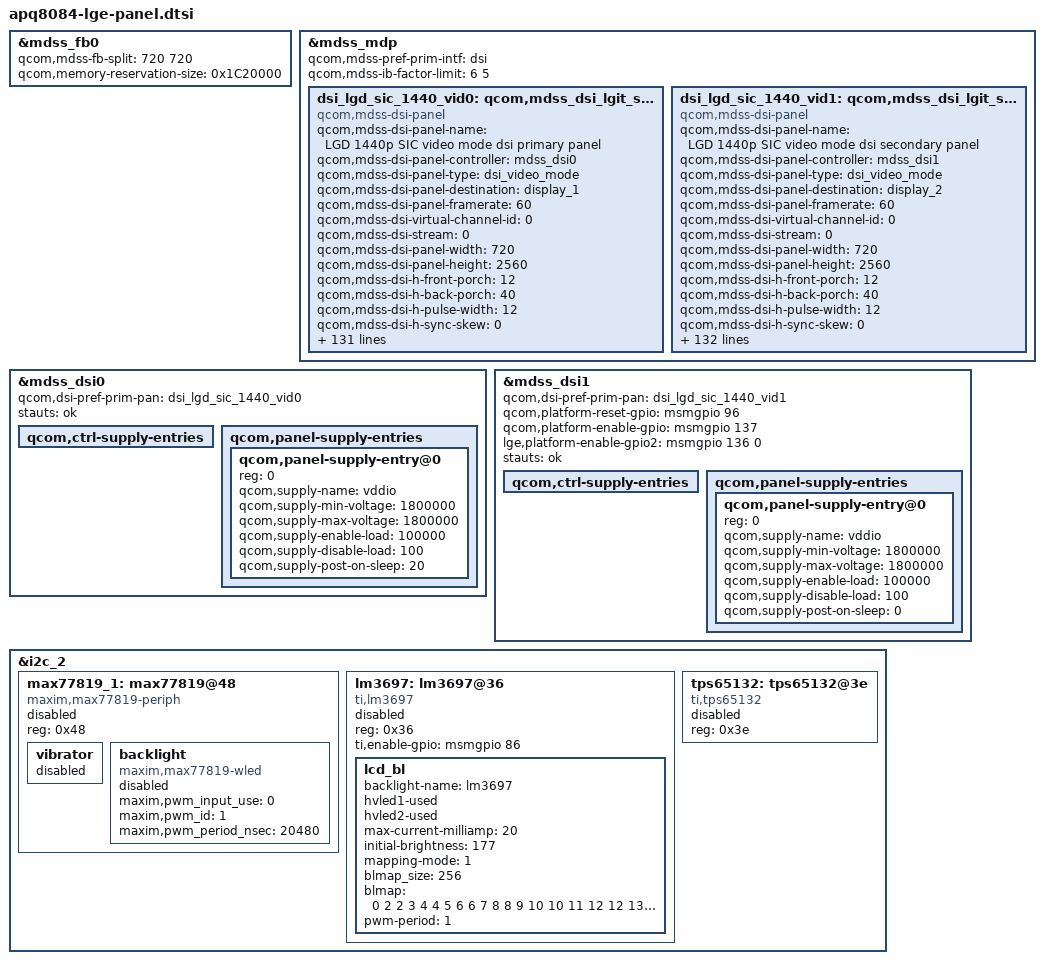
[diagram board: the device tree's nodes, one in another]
/* Copyright (c) 2012, Code Aurora Forum. All rights reserved.
 *
 * This program is free software; you can redistribute it and/or modify
 * it under the terms of the GNU General Public License version 2 and
 * only version 2 as published by the Free Software Foundation.
 *
 * This program is distributed in the hope that it will be useful,
 * but WITHOUT ANY WARRANTY; without even the implied warranty of
 * MERCHANTABILITY or FITNESS FOR A PARTICULAR PURPOSE.  See the
 * GNU General Public License for more details.
 */
&mdss_fb0 {
	/delete-property/ qcom,mdss-fb-splash-logo-enabled;
	qcom,mdss-fb-split = <720 720>;
	qcom,memory-reservation-size = <0x1C20000>;
};

&mdss_mdp {

	/delete-property/ qcom,mdss-ad-off;
    /delete-property/ qcom,mdss-has-source-split;
	qcom,mdss-pref-prim-intf = "dsi";
	qcom,mdss-ib-factor-limit = <6 5>;	/*  vt tuning times  */

	dsi_lgd_sic_1440_vid0: qcom,mdss_dsi_lgit_sic_mipi0_video {
		compatible = "qcom,mdss-dsi-panel";
		qcom,mdss-dsi-panel-name = "LGD 1440p SIC video mode dsi primary panel";
		qcom,mdss-dsi-panel-controller = <&mdss_dsi0>;
		qcom,mdss-dsi-panel-type = "dsi_video_mode";
		qcom,mdss-dsi-panel-destination = "display_1";
		qcom,mdss-dsi-panel-framerate = <60>;
		qcom,mdss-dsi-virtual-channel-id = <0>;
		qcom,mdss-dsi-stream = <0>;
		qcom,mdss-dsi-panel-width = <720>;
		qcom,mdss-dsi-panel-height = <2560>;
		qcom,mdss-dsi-h-front-porch = <12>;
		qcom,mdss-dsi-h-back-porch = <40>;
		qcom,mdss-dsi-h-pulse-width = <12>;
		qcom,mdss-dsi-h-sync-skew = <0>;
		qcom,mdss-dsi-v-back-porch = <5>;
		qcom,mdss-dsi-v-front-porch = <5>;
		qcom,mdss-dsi-v-pulse-width = <1>;
		qcom,mdss-dsi-h-left-border = <0>;
		qcom,mdss-dsi-h-right-border = <0>;
		qcom,mdss-dsi-v-top-border = <0>;
		qcom,mdss-dsi-v-bottom-border = <0>;
		qcom,mdss-dsi-bpp = <24>;
		qcom,mdss-dsi-color-order = "rgb_swap_rgb";
		qcom,mdss-dsi-underflow-color = <0x71>;
		qcom,mdss-dsi-border-color = <0>;
		qcom,mdss-dsi-on-command = [
			// SW reset
			05 01 00 00 05 00 01 01
			// Manufacturer Command Protection
			15 01 00 00 00 00 02 B0 AC
			// MIPI DSI Configuration
			39 01 00 00 00 00 06 B1 47 F0 80 00 00
			// MIPI DSI BIAS
			39 01 00 00 00 00 04 B2 77 28 27
			// Display Control. B3 ~ B5 : Control1 ~ Control3
			39 01 00 00 00 00 07 B3 0F 12 22 20 00 A0
			39 01 00 00 00 00 08 B4 13 10 10 0A 0A 0A 0A
			39 01 00 00 00 00 0A B5 30 26 1A 1A 10 10 40 10 05
			// Panel Setting
			39 01 00 00 00 00 04 B7 62 01 3F
			39 01 00 00 00 00 07 B8 00 00 00 47 7F 80
			39 01 00 00 00 00 03 C0 03 00
			39 01 00 00 00 00 06 C1 22 80 F0 01 CF
			// Power Control. C2 ~ C5 : Control2 ~ Control5
			15 01 00 00 00 00 02 C2 22
			39 01 00 00 00 00 07 C3 06 88 0C 00 1B 1B
			39 01 00 00 00 00 04 C4 47 0C 0C
			39 01 00 00 00 00 07 C5 41 81 05 05 59 02
			// Video Sync Output Control
			39 01 00 00 00 00 03 CA 20 B9
			// Abrupt Power Detect Configuration
			39 01 00 00 00 00 02 C9 3F
			// Gamma. P : Posi., N : Nega., R : Red, G : Green, B : Blue
			// D0 : PR, D1 : NR, D2 : PG, D3 : NG, D4 : PB, D5 : NB
			39 01 00 00 00 00 0C D0 03 30 35 55 22 34 0F 06 51 33 02
			39 01 00 00 00 00 0C D1 03 30 35 55 22 34 0F 06 51 33 02
			39 01 00 00 00 00 0C D2 03 30 35 55 22 34 0F 06 51 33 02
			39 01 00 00 00 00 0C D3 03 30 35 55 22 34 0F 06 51 33 02
			39 01 00 00 00 00 0C D4 03 30 35 55 22 34 0F 06 51 33 02
			39 01 00 00 00 00 0C D5 03 30 35 55 22 34 0F 06 51 33 02
			// Test 2
			39 01 00 00 00 00 05 E9 00 00 00 00
			// Pamper Control
			39 01 00 00 00 00 03 B6 00 00
			15 01 00 00 00 00 02 51 FF
			15 01 00 00 00 00 02 5E 00
			15 01 00 00 00 00 02 53 2C
			// 12.5%, 20kHz
			39 01 00 00 00 00 07 B8 11 11 11 38 00 00
			15 01 00 00 00 00 02 55 81
			15 01 00 00 00 00 02 F0 33
			// Contrast
			39 01 00 00 00 00 05 F1 00 00 02 02
			// Sharpness
			39 01 00 00 00 00 04 F2 01 00 40
			// Color enhancement
			39 01 00 00 00 00 06 F3 00 00 00 00 00
			// Selective Color. F4 ~ F7 : Color0 ~ Color4
			39 01 00 00 00 00 02 F4 05
			39 01 00 00 00 00 04 F5 02 00 83
			39 01 00 00 00 00 04 F6 00 00 00
			39 01 00 00 00 00 04 F7 00 00 00
			// Digital Gamma. RGB
			39 01 00 00 00 00 11 F8 40 40 40 40 40 40 40 40 00 00 00 00 00 00 00 00
			39 01 00 00 00 00 11 F9 40 40 40 40 40 40 40 40 00 00 00 00 00 00 00 00
			39 01 00 00 00 00 11 FA 40 40 40 40 40 40 40 40 00 00 00 00 00 00 00 00
			// sleep out delay 5ms
			05 01 00 00 05 00 01 11
			// display on delay 0ms
			05 01 00 00 00 00 01 29
			];
		qcom,mdss-dsi-off-command = [05 01 00 00 14 00 01 28
			05 01 00 00 50 00 01 10];
		qcom,mdss-dsi-on-command-state = "dsi_lp_mode";
		qcom,mdss-dsi-off-command-state = "dsi_hs_mode";
		qcom,mdss-dsi-h-sync-pulse = <0>;
		qcom,mdss-dsi-traffic-mode = "non_burst_sync_event";
		qcom,mdss-dsi-lane-map = "lane_map_0123";
		qcom,mdss-dsi-lane-hs = <1>;
		qcom,mdss-dsi-bllp-eof-power-mode;
		qcom,mdss-dsi-bllp-power-mode;
		qcom,mdss-dsi-lane-0-state;
		qcom,mdss-dsi-lane-1-state;
		qcom,mdss-dsi-lane-2-state;
		qcom,mdss-dsi-lane-3-state;
		qcom,cmd-sync-wait-broadcast;
		qcom,mdss-dsi-panel-timings = [C5 2C 1E 00 5A 5E
			22 30 25 03 04 00];
		qcom,mdss-dsi-t-clk-post = <0x03>;
		qcom,mdss-dsi-t-clk-pre = <0x25>;
		qcom,mdss-dsi-bl-min-level = <1>;
		qcom,mdss-dsi-bl-max-level = <255>;
		qcom,mdss-dsi-dma-trigger = "trigger_sw";
		qcom,mdss-dsi-mdp-trigger = "none";
		qcom,mdss-dsi-bl-pmic-control-type = "bl_others";
		qcom,mdss-dsi-reset-sequence = <1 5>;
		qcom,cont-splash-enabled;
		qcom,mdss-dsi-lp11-init;
		qcom,mdss-dsi-tx-eot-append;
		qcom,mdss-dsi-sharpening-lv0 = [ 39 01 00 00 00 00 04 F2 01 00 00 ]; 
		qcom,mdss-dsi-sharpening-lv1 = [ 39 01 00 00 00 00 04 F2 01 00 01 ]; 
		qcom,mdss-dsi-sharpening-lv2 = [ 39 01 00 00 00 00 04 F2 01 00 02 ]; 
		qcom,mdss-dsi-sharpening-lv3 = [ 39 01 00 00 00 00 04 F2 01 00 03 ]; 
		qcom,mdss-dsi-sharpening-lv4 = [ 39 01 00 00 00 00 04 F2 01 00 04 ]; 
		qcom,mdss-dsi-sharpening-lv5 = [ 39 01 00 00 00 00 04 F2 01 00 05 ]; 
		qcom,mdss-dsi-sharpening-lv6 = [ 39 01 00 00 00 00 04 F2 01 00 06 ]; 
		qcom,mdss-dsi-sharpening-lv7 = [ 39 01 00 00 00 00 04 F2 01 00 07 ]; 
		qcom,mdss-dsi-sharpening-lv8 = [ 39 01 00 00 00 00 04 F2 01 00 08 ]; 
		qcom,mdss-dsi-sharpening-lv9 = [ 39 01 00 00 00 00 04 F2 01 00 09 ]; 
		qcom,mdss-dsi-sharpening-lv10 = [ 39 01 00 00 00 00 04 F2 01 00 10 ]; 
		qcom,mdss-dsi-sharpening-lv11 = [ 39 01 00 00 00 00 04 F2 01 00 11 ]; 
		qcom,mdss-dsi-sharpening-lv12 = [ 39 01 00 00 00 00 04 F2 01 00 12 ]; 
		qcom,mdss-dsi-sharpening-lv13 = [ 39 01 00 00 00 00 04 F2 01 00 13 ]; 
		qcom,mdss-dsi-sharpening-lv14 = [ 39 01 00 00 00 00 04 F2 01 00 14 ]; 
		qcom,mdss-dsi-sharpening-lv15 = [ 39 01 00 00 00 00 04 F2 01 00 15 ]; 
		qcom,mdss-dsi-sharpening-lv16 = [ 39 01 00 00 00 00 04 F2 01 00 16 ]; 
		qcom,mdss-dsi-sharpening-lv17 = [ 39 01 00 00 00 00 04 F2 01 00 17 ]; 
		qcom,mdss-dsi-sharpening-lv18 = [ 39 01 00 00 00 00 04 F2 01 00 18 ]; 
		qcom,mdss-dsi-sharpening-lv19 = [ 39 01 00 00 00 00 04 F2 01 00 19 ]; 
		qcom,mdss-dsi-sharpening-lv20 = [ 39 01 00 00 00 00 04 F2 01 00 20 ]; 
		qcom,mdss-dsi-sharpening-lv21 = [ 39 01 00 00 00 00 04 F2 01 00 21 ]; 
		qcom,mdss-dsi-sharpening-lv22 = [ 39 01 00 00 00 00 04 F2 01 00 22 ]; 
		qcom,mdss-dsi-sharpening-lv23 = [ 39 01 00 00 00 00 04 F2 01 00 23 ]; 
		qcom,mdss-dsi-sharpening-lv24 = [ 39 01 00 00 00 00 04 F2 01 00 24 ]; 
		qcom,mdss-dsi-sharpening-lv25 = [ 39 01 00 00 00 00 04 F2 01 00 25 ]; 
		qcom,mdss-dsi-sharpening-lv26 = [ 39 01 00 00 00 00 04 F2 01 00 26 ]; 
		qcom,mdss-dsi-sharpening-lv27 = [ 39 01 00 00 00 00 04 F2 01 00 27 ]; 
		qcom,mdss-dsi-sharpening-lv28 = [ 39 01 00 00 00 00 04 F2 01 00 28 ]; 
		qcom,mdss-dsi-sharpening-lv29 = [ 39 01 00 00 00 00 04 F2 01 00 29 ]; 
		qcom,mdss-dsi-sharpening-lv30 = [ 39 01 00 00 00 00 04 F2 01 00 30 ]; 
		qcom,mdss-dsi-sharpening-lv31 = [ 39 01 00 00 00 00 04 F2 01 00 31 ]; 
		qcom,mdss-dsi-sharpening-lv32 = [ 39 01 00 00 00 00 04 F2 01 00 32 ]; 
		qcom,mdss-dsi-sharpening-lv33 = [ 39 01 00 00 00 00 04 F2 01 00 33 ]; 
		qcom,mdss-dsi-sharpening-lv34 = [ 39 01 00 00 00 00 04 F2 01 00 34 ]; 
		qcom,mdss-dsi-sharpening-lv35 = [ 39 01 00 00 00 00 04 F2 01 00 35 ]; 
		qcom,mdss-dsi-sharpening-lv36 = [ 39 01 00 00 00 00 04 F2 01 00 36 ]; 
		qcom,mdss-dsi-sharpening-lv37 = [ 39 01 00 00 00 00 04 F2 01 00 37 ]; 
		qcom,mdss-dsi-sharpening-lv38 = [ 39 01 00 00 00 00 04 F2 01 00 38 ]; 
		qcom,mdss-dsi-sharpening-lv39 = [ 39 01 00 00 00 00 04 F2 01 00 39 ]; 
		qcom,mdss-dsi-sharpening-lv40 = [ 39 01 00 00 00 00 04 F2 01 00 40 ];
 		qcom,mdss-dsi-sharpening-mode = "dsi_hs_mode";

		// ief
		qcom,panel-ief-on-cmds = [
			15 01 00 00 00 00 02 B0 AC
			15 01 00 00 00 00 02 55 81
			15 01 00 00 00 00 02 F0 7F
			39 01 00 00 00 00 05 F1 00 00 01 01
			39 01 00 00 00 00 04 F2 04 00 80
			39 01 00 00 00 00 06 F3 00 00 00 00 00
			39 01 00 00 00 00 03 F4 00 14
			39 01 00 00 00 00 04 F5 07 00 03
			39 01 00 00 00 00 04 F6 00 00 00
			39 01 00 00 00 00 04 F7 00 00 00
			39 01 00 00 00 00 11 F8 40 40 40 40 40 40 40 40 00 00 00 00 00 00 00 00
			39 01 00 00 00 00 11 F9 40 40 40 40 40 40 40 40 00 00 00 00 00 00 00 00
			39 01 00 00 00 00 11 FA 40 40 40 40 40 40 40 40 00 00 00 00 00 00 00 00
			];
		qcom,panel-ief-off-cmds = [
			15 01 00 00 00 00 02 B0 AC
			15 01 00 00 00 00 02 55 81
			15 01 00 00 00 00 02 F0 26
			39 01 00 00 00 00 05 F1 00 00 00 00
			39 01 00 00 00 00 04 F2 01 00 40
			39 01 00 00 00 00 06 F3 00 00 00 00 00
			39 01 00 00 00 00 02 F4 05
			39 01 00 00 00 00 04 F5 02 00 83
			39 01 00 00 00 00 04 F6 00 00 00
			39 01 00 00 00 00 04 F7 00 00 00
			39 01 00 00 00 00 11 F8 40 40 40 40 40 40 40 40 00 00 00 00 00 00 00 00
			39 01 00 00 00 00 11 F9 40 40 40 40 40 40 40 40 00 00 00 00 00 00 00 00
			39 01 00 00 00 00 11 FA 40 40 40 40 40 40 40 40 00 00 00 00 00 00 00 00
			];
		qcom,ief-on-dsi-state = "dsi_hs_mode";
		qcom,ief-off-dsi-state = "dsi_hs_mode";
	};
	dsi_lgd_sic_1440_vid1: qcom,mdss_dsi_lgit_sic_mipi1_video {
		compatible = "qcom,mdss-dsi-panel";
		qcom,mdss-dsi-panel-name = "LGD 1440p SIC video mode dsi secondary panel";
		qcom,mdss-dsi-panel-controller = <&mdss_dsi1>;
		qcom,mdss-dsi-panel-type = "dsi_video_mode";
		qcom,mdss-dsi-panel-destination = "display_2";
		qcom,mdss-dsi-panel-framerate = <60>;
		qcom,mdss-dsi-virtual-channel-id = <0>;
		qcom,mdss-dsi-stream = <0>;
		qcom,mdss-dsi-panel-width = <720>;
		qcom,mdss-dsi-panel-height = <2560>;
		qcom,mdss-dsi-h-front-porch = <12>;
		qcom,mdss-dsi-h-back-porch = <40>;
		qcom,mdss-dsi-h-pulse-width = <12>;
		qcom,mdss-dsi-h-sync-skew = <0>;
		qcom,mdss-dsi-v-back-porch = <5>;
		qcom,mdss-dsi-v-front-porch = <5>;
		qcom,mdss-dsi-v-pulse-width = <1>;
		qcom,mdss-dsi-h-left-border = <0>;
		qcom,mdss-dsi-h-right-border = <0>;
		qcom,mdss-dsi-v-top-border = <0>;
		qcom,mdss-dsi-v-bottom-border = <0>;
		qcom,mdss-dsi-bpp = <24>;
		qcom,mdss-dsi-color-order = "rgb_swap_rgb";
		qcom,mdss-dsi-underflow-color = <0x71>;
		qcom,mdss-dsi-border-color = <0>;
		qcom,mdss-dsi-on-command = [
			// SW reset
			05 01 00 00 05 00 01 01
			// Manufacturer Command Protection
			15 01 00 00 00 00 02 B0 AC
			// MIPI DSI Configuration
			39 01 00 00 00 00 06 B1 47 F0 80 00 00
			// MIPI DSI BIAS
			39 01 00 00 00 00 04 B2 77 28 27
			// Display Control. B3 ~ B5 : Control1 ~ Control3
			39 01 00 00 00 00 07 B3 0F 12 22 20 00 A0
			39 01 00 00 00 00 08 B4 13 10 10 0A 0A 0A 0A
			39 01 00 00 00 00 0A B5 30 26 1A 1A 10 10 40 10 05
			// Panel Setting
			39 01 00 00 00 00 04 B7 62 01 3F
			39 01 00 00 00 00 07 B8 00 00 00 47 7F 80
			39 01 00 00 00 00 03 C0 03 00
			39 01 00 00 00 00 06 C1 22 80 F0 01 CF
			// Power Control. C2 ~ C5 : Control2 ~ Control5
			15 01 00 00 00 00 02 C2 22
			39 01 00 00 00 00 07 C3 06 88 0C 00 1B 1B
			39 01 00 00 00 00 04 C4 47 0C 0C
			39 01 00 00 00 00 07 C5 41 81 05 05 59 02
			// Video Sync Output Control
			39 01 00 00 00 00 03 CA 20 B9
			// Abrupt Power Detect Configuration
			39 01 00 00 00 00 02 C9 3F
			// Gamma. P : Posi., N : Nega., R : Red, G : Green, B : Blue
			// D0 : PR, D1 : NR, D2 : PG, D3 : NG, D4 : PB, D5 : NB
			39 01 00 00 00 00 0C D0 03 30 35 55 22 34 0F 06 51 33 02
			39 01 00 00 00 00 0C D1 03 30 35 55 22 34 0F 06 51 33 02
			39 01 00 00 00 00 0C D2 03 30 35 55 22 34 0F 06 51 33 02
			39 01 00 00 00 00 0C D3 03 30 35 55 22 34 0F 06 51 33 02
			39 01 00 00 00 00 0C D4 03 30 35 55 22 34 0F 06 51 33 02
			39 01 00 00 00 00 0C D5 03 30 35 55 22 34 0F 06 51 33 02
			// Test 2
			39 01 00 00 00 00 05 E9 00 00 00 00
			// Pamper Control
			39 01 00 00 00 00 03 B6 00 00
			15 01 00 00 00 00 02 51 FF
			15 01 00 00 00 00 02 5E 00
			15 01 00 00 00 00 02 53 2C
			// 12.5%, 20kHz
			39 01 00 00 00 00 07 B8 11 11 11 38 00 00
			15 01 00 00 00 00 02 55 81
			15 01 00 00 00 00 02 F0 33
			// Contrast
			39 01 00 00 00 00 05 F1 00 00 02 02
			// Sharpness
			39 01 00 00 00 00 04 F2 01 00 40
			// Color enhancement
			39 01 00 00 00 00 06 F3 00 00 00 00 00
			// Selective Color. F4 ~ F7 : Color0 ~ Color4
			39 01 00 00 00 00 02 F4 05
			39 01 00 00 00 00 04 F5 02 00 83
			39 01 00 00 00 00 04 F6 00 00 00
			39 01 00 00 00 00 04 F7 00 00 00
			// Digital Gamma. RGB
			39 01 00 00 00 00 11 F8 40 40 40 40 40 40 40 40 00 00 00 00 00 00 00 00
			39 01 00 00 00 00 11 F9 40 40 40 40 40 40 40 40 00 00 00 00 00 00 00 00
			39 01 00 00 00 00 11 FA 40 40 40 40 40 40 40 40 00 00 00 00 00 00 00 00
			// sleep out delay 5ms
			05 01 00 00 05 00 01 11
			// display on delay 0ms
			05 01 00 00 00 00 01 29
			];
		qcom,mdss-dsi-off-command = [05 01 00 00 14 00 01 28
			05 01 00 00 50 00 01 10];
		qcom,mdss-dsi-on-command-state = "dsi_lp_mode";
		qcom,mdss-dsi-off-command-state = "dsi_hs_mode";
		qcom,mdss-dsi-h-sync-pulse = <0>;
		qcom,mdss-dsi-traffic-mode = "non_burst_sync_event";
		qcom,mdss-dsi-lane-map = "lane_map_0123";
		qcom,mdss-dsi-lane-hs = <1>;
		qcom,mdss-dsi-bllp-eof-power-mode;
		qcom,mdss-dsi-bllp-power-mode;
		qcom,mdss-dsi-lane-0-state;
		qcom,mdss-dsi-lane-1-state;
		qcom,mdss-dsi-lane-2-state;
		qcom,mdss-dsi-lane-3-state;
		qcom,cmd-sync-wait-broadcast;
		qcom,cmd-sync-wait-trigger;
		qcom,mdss-dsi-panel-timings = [C5 2C 1E 00 5A 5E
			22 30 25 03 04 00];
		qcom,mdss-dsi-t-clk-post = <0x03>;
		qcom,mdss-dsi-t-clk-pre = <0x25>;
		qcom,mdss-dsi-bl-min-level = <1>;
		qcom,mdss-dsi-bl-max-level = <255>;
		qcom,mdss-dsi-dma-trigger = "trigger_sw";
		qcom,mdss-dsi-mdp-trigger = "none";
		qcom,mdss-dsi-bl-pmic-control-type = "bl_others";
		qcom,mdss-dsi-reset-sequence = <1 5>;
		qcom,cont-splash-enabled;
		qcom,mdss-dsi-lp11-init;
		qcom,mdss-dsi-tx-eot-append;
		qcom,mdss-dsi-sharpening-lv0 = [ 39 01 00 00 00 00 04 F2 01 00 00 ]; 
		qcom,mdss-dsi-sharpening-lv1 = [ 39 01 00 00 00 00 04 F2 01 00 01 ]; 
		qcom,mdss-dsi-sharpening-lv2 = [ 39 01 00 00 00 00 04 F2 01 00 02 ]; 
		qcom,mdss-dsi-sharpening-lv3 = [ 39 01 00 00 00 00 04 F2 01 00 03 ]; 
		qcom,mdss-dsi-sharpening-lv4 = [ 39 01 00 00 00 00 04 F2 01 00 04 ]; 
		qcom,mdss-dsi-sharpening-lv5 = [ 39 01 00 00 00 00 04 F2 01 00 05 ]; 
		qcom,mdss-dsi-sharpening-lv6 = [ 39 01 00 00 00 00 04 F2 01 00 06 ]; 
		qcom,mdss-dsi-sharpening-lv7 = [ 39 01 00 00 00 00 04 F2 01 00 07 ]; 
		qcom,mdss-dsi-sharpening-lv8 = [ 39 01 00 00 00 00 04 F2 01 00 08 ]; 
		qcom,mdss-dsi-sharpening-lv9 = [ 39 01 00 00 00 00 04 F2 01 00 09 ]; 
		qcom,mdss-dsi-sharpening-lv10 = [ 39 01 00 00 00 00 04 F2 01 00 10 ]; 
		qcom,mdss-dsi-sharpening-lv11 = [ 39 01 00 00 00 00 04 F2 01 00 11 ]; 
		qcom,mdss-dsi-sharpening-lv12 = [ 39 01 00 00 00 00 04 F2 01 00 12 ]; 
		qcom,mdss-dsi-sharpening-lv13 = [ 39 01 00 00 00 00 04 F2 01 00 13 ]; 
		qcom,mdss-dsi-sharpening-lv14 = [ 39 01 00 00 00 00 04 F2 01 00 14 ]; 
		qcom,mdss-dsi-sharpening-lv15 = [ 39 01 00 00 00 00 04 F2 01 00 15 ]; 
		qcom,mdss-dsi-sharpening-lv16 = [ 39 01 00 00 00 00 04 F2 01 00 16 ]; 
		qcom,mdss-dsi-sharpening-lv17 = [ 39 01 00 00 00 00 04 F2 01 00 17 ]; 
		qcom,mdss-dsi-sharpening-lv18 = [ 39 01 00 00 00 00 04 F2 01 00 18 ]; 
		qcom,mdss-dsi-sharpening-lv19 = [ 39 01 00 00 00 00 04 F2 01 00 19 ]; 
		qcom,mdss-dsi-sharpening-lv20 = [ 39 01 00 00 00 00 04 F2 01 00 20 ]; 
		qcom,mdss-dsi-sharpening-lv21 = [ 39 01 00 00 00 00 04 F2 01 00 21 ]; 
		qcom,mdss-dsi-sharpening-lv22 = [ 39 01 00 00 00 00 04 F2 01 00 22 ]; 
		qcom,mdss-dsi-sharpening-lv23 = [ 39 01 00 00 00 00 04 F2 01 00 23 ]; 
		qcom,mdss-dsi-sharpening-lv24 = [ 39 01 00 00 00 00 04 F2 01 00 24 ]; 
		qcom,mdss-dsi-sharpening-lv25 = [ 39 01 00 00 00 00 04 F2 01 00 25 ]; 
		qcom,mdss-dsi-sharpening-lv26 = [ 39 01 00 00 00 00 04 F2 01 00 26 ]; 
		qcom,mdss-dsi-sharpening-lv27 = [ 39 01 00 00 00 00 04 F2 01 00 27 ]; 
		qcom,mdss-dsi-sharpening-lv28 = [ 39 01 00 00 00 00 04 F2 01 00 28 ]; 
		qcom,mdss-dsi-sharpening-lv29 = [ 39 01 00 00 00 00 04 F2 01 00 29 ]; 
		qcom,mdss-dsi-sharpening-lv30 = [ 39 01 00 00 00 00 04 F2 01 00 30 ]; 
		qcom,mdss-dsi-sharpening-lv31 = [ 39 01 00 00 00 00 04 F2 01 00 31 ]; 
		qcom,mdss-dsi-sharpening-lv32 = [ 39 01 00 00 00 00 04 F2 01 00 32 ]; 
		qcom,mdss-dsi-sharpening-lv33 = [ 39 01 00 00 00 00 04 F2 01 00 33 ]; 
		qcom,mdss-dsi-sharpening-lv34 = [ 39 01 00 00 00 00 04 F2 01 00 34 ]; 
		qcom,mdss-dsi-sharpening-lv35 = [ 39 01 00 00 00 00 04 F2 01 00 35 ]; 
		qcom,mdss-dsi-sharpening-lv36 = [ 39 01 00 00 00 00 04 F2 01 00 36 ]; 
		qcom,mdss-dsi-sharpening-lv37 = [ 39 01 00 00 00 00 04 F2 01 00 37 ]; 
		qcom,mdss-dsi-sharpening-lv38 = [ 39 01 00 00 00 00 04 F2 01 00 38 ]; 
		qcom,mdss-dsi-sharpening-lv39 = [ 39 01 00 00 00 00 04 F2 01 00 39 ]; 
		qcom,mdss-dsi-sharpening-lv40 = [ 39 01 00 00 00 00 04 F2 01 00 40 ];
 		qcom,mdss-dsi-sharpening-mode = "dsi_hs_mode";

		// ief
		qcom,panel-ief-on-cmds = [
			15 01 00 00 00 00 02 B0 AC
			15 01 00 00 00 00 02 55 81
			15 01 00 00 00 00 02 F0 7F
			39 01 00 00 00 00 05 F1 00 00 01 01
			39 01 00 00 00 00 04 F2 04 00 80
			39 01 00 00 00 00 06 F3 00 00 00 00 00
			39 01 00 00 00 00 03 F4 00 14
			39 01 00 00 00 00 04 F5 07 00 03
			39 01 00 00 00 00 04 F6 00 00 00
			39 01 00 00 00 00 04 F7 00 00 00
			39 01 00 00 00 00 11 F8 40 40 40 40 40 40 40 40 00 00 00 00 00 00 00 00
			39 01 00 00 00 00 11 F9 40 40 40 40 40 40 40 40 00 00 00 00 00 00 00 00
			39 01 00 00 00 00 11 FA 40 40 40 40 40 40 40 40 00 00 00 00 00 00 00 00
			];
		qcom,panel-ief-off-cmds = [
			15 01 00 00 00 00 02 B0 AC
			15 01 00 00 00 00 02 55 81
			15 01 00 00 00 00 02 F0 26
			39 01 00 00 00 00 05 F1 00 00 00 00
			39 01 00 00 00 00 04 F2 01 00 40
			39 01 00 00 00 00 06 F3 00 00 00 00 00
			39 01 00 00 00 00 02 F4 05
			39 01 00 00 00 00 04 F5 02 00 83
			39 01 00 00 00 00 04 F6 00 00 00
			39 01 00 00 00 00 04 F7 00 00 00
			39 01 00 00 00 00 11 F8 40 40 40 40 40 40 40 40 00 00 00 00 00 00 00 00
			39 01 00 00 00 00 11 F9 40 40 40 40 40 40 40 40 00 00 00 00 00 00 00 00
			39 01 00 00 00 00 11 FA 40 40 40 40 40 40 40 40 00 00 00 00 00 00 00 00
			];
		qcom,ief-on-dsi-state = "dsi_hs_mode";
		qcom,ief-off-dsi-state = "dsi_hs_mode";
	};
};

&mdss_dsi0 {
	/delete-property/ qcom,platform-bklight-en-gpio;
	/delete-property/ qcom,platform-reset-gpio;
	/delete-property/ qcom,platform-enable-gpio;
	qcom,dsi-pref-prim-pan = <&dsi_lgd_sic_1440_vid0>;
	stauts = "ok";
	qcom,ctrl-supply-entries {
		/delete-node/ qcom,ctrl-supply-entry@1;
	};

	qcom,panel-supply-entries {
		#address-cells = <1>;
		#size-cells = <0>;

		qcom,panel-supply-entry@0 {
			reg = <0>;
			qcom,supply-name = "vddio";
			qcom,supply-min-voltage = <1800000>;
			qcom,supply-max-voltage = <1800000>;
			qcom,supply-enable-load = <100000>;
			qcom,supply-disable-load = <100>;
			qcom,supply-post-on-sleep = <20>;
		};

		/delete-node/ qcom,panel-supply-entry@1;
	};

};

&mdss_dsi1 {
	qcom,dsi-pref-prim-pan = <&dsi_lgd_sic_1440_vid1>;
	qcom,platform-reset-gpio = <&msmgpio 96 0>;
	qcom,platform-enable-gpio = <&msmgpio 137 0>;
	lge,platform-enable-gpio2 = <&msmgpio 136 0>;
	stauts = "ok";
	qcom,ctrl-supply-entries {
		/delete-node/ qcom,ctrl-supply-entry@1;
	};

	qcom,panel-supply-entries {
		#address-cells = <1>;
		#size-cells = <0>;

		qcom,panel-supply-entry@0 {
			reg = <0>;
			qcom,supply-name = "vddio";
			qcom,supply-min-voltage = <1800000>;
			qcom,supply-max-voltage = <1800000>;
			qcom,supply-enable-load = <100000>;
			qcom,supply-disable-load = <100>;
			qcom,supply-post-on-sleep = <0>;
		};

		/delete-node/ qcom,panel-supply-entry@1;
	};

};

&i2c_2 {
	max77819_1: max77819@48 {
		compatible = "maxim,max77819-periph";
		reg = <0x48>;
		status = "disable";

		vibrator {
			status = "disable";
		};

		backlight {
			compatible = "maxim,max77819-wled";
			maxim,pwm_input_use = <0>;
			maxim,pwm_id = <1>;
			maxim,pwm_period_nsec = <20480>; /* 1024*20 */
			status = "disable";
		};
	};

	lm3697: lm3697@36 {
		compatible = "ti,lm3697";
		status = "disable";
		reg = <0x36>;

		/* GPIO134 for HWEN pin */
		ti,enable-gpio = <&msmgpio 86 0x00>;

		lcd_bl {
			backlight-name = "lm3697";
			hvled1-used;
			hvled2-used;

			max-current-milliamp = <20>;
			initial-brightness = <177>;
			/* mapping-mode, 0:exp, 1:linear */
			mapping-mode = <1>;

			blmap_size = <256>;
			blmap = <
				0 2 2 3 4 4 5 6 6 7 8 8 9 10 10 11 12 12 13 14 14 15 16 16
				17 18 18 19 19 20 21 21 22 23 23 24 25 25 26 27 27 28 29 29
				30 31 31 32 33 33 34 34 34 35 35 35 35 35 35 36 36 36 36 37
				38 39 40 40 41 42 43 44 45 47 48 50 51 53 54 56 57 59 60 62
				64 67 69 71 73 75 78 80 82 85 89 92 96 99 102 106 109 113
				116 120 123 127 131 134 138 141 145 149 152 156 161 167 172
				178 183 189 194 200 205 210 215 220 225 230 235 239 244 249
				254 259 264 271 277 284 291 297 304 311 317 324 332 340 348
				356 364 371 379 387 395 403 411 420 429 438 447 457 466 475
				484 493 502 511 520 529 538 547 555 564 573 582 591 600 612
				625 637 650 662 675 687 700 712 725 737 750 762 775 788 800
				813 825 838 851 863 876 888 901 913 926 938 951 963 976 990
				1004 1018 1032 1046 1060 1074 1088 1116 1124 1130 1146 1163
				1179 1196 1212 1228 1245 1261 1278 1294 1312 1331 1349 1368
				1386 1404 1423 1441 1460 1478 1498 1518 1539 1559 1579 1599
				1619 1640 1660 1680 1704 1727 1751 1774 1798 1821 1845 1868
				1892
			>;

			pwm-period = <1>;
		};
	};

	tps65132: tps65132@3e {
		compatible = "ti,tps65132";
		status = "disable";
		reg = <0x3e>;
	};
};
